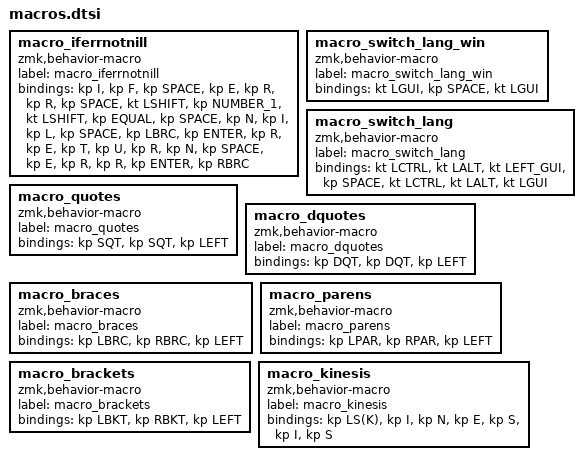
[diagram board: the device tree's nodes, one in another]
macro_iferrnotnill: macro_iferrnotnill{
compatible = "zmk,behavior-macro";
label = "macro_iferrnotnill";
#binding-cells = <0>;
bindings = <&kp I>, <&kp F>, <&kp SPACE>, <&kp E>, <&kp R>, <&kp R>, <&kp SPACE>, <&kt LSHIFT>, <&kp NUMBER_1>, <&kt LSHIFT>, <&kp EQUAL>, <&kp SPACE>, <&kp N>, <&kp I>, <&kp L>, <&kp SPACE>, <&kp LBRC>, <&kp ENTER>, <&kp R>, <&kp E>, <&kp T>, <&kp U>, <&kp R>, <&kp N>, <&kp SPACE>, <&kp E>, <&kp R>, <&kp R>, <&kp ENTER>, <&kp RBRC>;
};
macro_switch_lang_win: macro_switch_lang_win{
compatible = "zmk,behavior-macro";
label = "macro_switch_lang_win";
#binding-cells = <0>;
bindings = <&kt LGUI>, <&kp SPACE>, <&kt LGUI>;
};
macro_switch_lang: macro_switch_lang{
compatible = "zmk,behavior-macro";
label = "macro_switch_lang";
#binding-cells = <0>;
bindings = <&kt LCTRL>, <&kt LALT>, <&kt LEFT_GUI>, <&kp SPACE>, <&kt LCTRL>, <&kt LALT>, <&kt LGUI>;
};
macro_quotes: macro_quotes{
compatible = "zmk,behavior-macro";
label = "macro_quotes";
#binding-cells = <0>;
bindings = <&kp SQT>, <&kp SQT>, <&kp LEFT>;
};
macro_dquotes: macro_dquotes{
compatible = "zmk,behavior-macro";
label = "macro_dquotes";
#binding-cells = <0>;
bindings = <&kp DQT>, <&kp DQT>, <&kp LEFT>;
};
macro_braces: macro_braces{
compatible = "zmk,behavior-macro";
label = "macro_braces";
#binding-cells = <0>;
bindings = <&kp LBRC>, <&kp RBRC>, <&kp LEFT>;
};
macro_parens: macro_parens{
compatible = "zmk,behavior-macro";
label = "macro_parens";
#binding-cells = <0>;
bindings = <&kp LPAR>, <&kp RPAR>, <&kp LEFT>;
};
macro_brackets: macro_brackets{
compatible = "zmk,behavior-macro";
label = "macro_brackets";
#binding-cells = <0>;
bindings = <&kp LBKT>, <&kp RBKT>, <&kp LEFT>;
};
macro_kinesis: macro_kinesis{
compatible = "zmk,behavior-macro";
label = "macro_kinesis";
#binding-cells = <0>;
bindings = <&kp LS(K)>, <&kp I>, <&kp N>, <&kp E>, <&kp S>, <&kp I>, <&kp S>;
};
